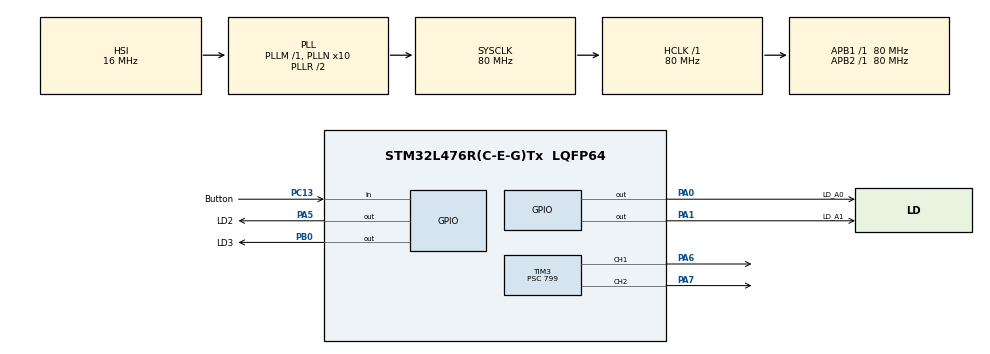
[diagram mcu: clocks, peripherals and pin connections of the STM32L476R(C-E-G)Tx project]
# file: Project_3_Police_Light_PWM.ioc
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Mcu.Family=STM32L4
Mcu.Name=STM32L476R(C-E-G)Tx
Mcu.Package=LQFP64
NVIC.PriorityGroup=NVIC_PRIORITYGROUP_4
NVIC.TIM3_IRQn=true\:10\:0\:true\:false\:true\:true\:true\:true
NVIC.TIM4_IRQn=true\:10\:0\:true\:false\:true\:true\:true\:true
PA0.GPIO_Label=LD_A0
PA0.Signal=GPIO_Output
PA1.GPIO_Label=LD_A1
PA1.Signal=GPIO_Output
PA5.GPIO_Label=LD2
PA5.Signal=GPIO_Output
PA6.Signal=S_TIM3_CH1
PA7.Signal=S_TIM3_CH2
PB0.GPIO_Label=LD3
PB0.Signal=GPIO_Output
PC13.GPIO_Label=Button
PC13.Signal=GPIO_Input
ProjectManager.HeapSize=0x200
ProjectManager.StackSize=0x400
ProjectManager.TargetToolchain=STM32CubeIDE
RCC.ADCFreq_Value=64000000
RCC.AHBFreq_Value=80000000
RCC.APB1Freq_Value=80000000
RCC.APB1TimFreq_Value=80000000
RCC.APB2Freq_Value=80000000
RCC.APB2TimFreq_Value=80000000
RCC.CortexFreq_Value=80000000
RCC.HCLKFreq_Value=80000000
RCC.HSE_VALUE=8000000
RCC.HSI_VALUE=16000000
RCC.LSE_VALUE=32768
RCC.MSI_VALUE=4000000
RCC.PLLN=10
RCC.PLLSourceVirtual=RCC_PLLSOURCE_HSI
RCC.PREFETCH_ENABLE=1
RCC.SYSCLKFreq_VALUE=80000000
RCC.SYSCLKSource=RCC_SYSCLKSOURCE_PLLCLK
RCC.USBFreq_Value=64000000
RCC.VCOOutputFreq_Value=160000000
SH.S_TIM3_CH1.0=TIM3_CH1,PWM Generation1 CH1
SH.S_TIM3_CH2.0=TIM3_CH2,PWM Generation2 CH2
TIM3.Channel-Output\ Compare3\ No\ Output=TIM_CHANNEL_3
TIM3.Channel-PWM\ Generation1\ CH1=TIM_CHANNEL_1
TIM3.Channel-PWM\ Generation2\ CH2=TIM_CHANNEL_2
TIM3.OCPolarity_1=TIM_OCPOLARITY_LOW
TIM3.OCPolarity_2=TIM_OCPOLARITY_HIGH
TIM3.OCPolarity_3=TIM_OCPOLARITY_HIGH
TIM3.Period=9999
TIM3.Prescaler=799
TIM3.Pulse-Output\ Compare3\ No\ Output=5000
TIM3.Pulse-PWM\ Generation1\ CH1=5000
TIM3.Pulse-PWM\ Generation2\ CH2=5000
TIM4.Channel-Output\ Compare1\ No\ Output=TIM_CHANNEL_1
TIM4.Period=9999
TIM4.Prescaler=799
TIM4.Pulse-Output\ Compare1\ No\ Output=5000
VP_TIM3_VS_ClockSourceINT.Mode=Internal
VP_TIM3_VS_no_output3.Mode=Output Compare3 No Output
VP_TIM4_VS_no_output1.Mode=Output Compare1 No Output
board=NUCLEO-L476RG

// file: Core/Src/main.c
/* USER CODE BEGIN Header */
/**
  ******************************************************************************
  * @file           : main.c
  * @brief          : Main program body
  ******************************************************************************
  * @attention
  *
  * Copyright (c) 2024 STMicroelectronics.
  * All rights reserved.
  *
  * This software is licensed under terms that can be found in the LICENSE file
  * in the root directory of this software component.
  * If no LICENSE file comes with this software, it is provided AS-IS.
  *
  ******************************************************************************
  */
/* USER CODE END Header */
#include "main.h"

TIM_HandleTypeDef htim3;
TIM_HandleTypeDef htim4;

void SystemClock_Config(void);
static void MX_GPIO_Init(void);
static void MX_TIM3_Init(void);
static void MX_TIM4_Init(void);

/* USER CODE BEGIN 0 */

void HAL_TIM_PeriodElapsedCallback(TIM_HandleTypeDef *htim)
{
  if (htim == &htim3) {
    HAL_GPIO_TogglePin(LD2_GPIO_Port, LD2_Pin);
  }
}
/* USER CODE END 0 */

int main(void)
{

  /* MCU Configuration--------------------------------------------------------*/

  /* Reset of all peripherals, Initializes the Flash interface and the Systick. */
  HAL_Init();

  /* Configure the system clock */
  SystemClock_Config();

  /* Initialize all configured peripherals */
  MX_GPIO_Init();
  MX_TIM3_Init();
  MX_TIM4_Init();
  /* USER CODE BEGIN 2 */

  HAL_TIM_Base_Start_IT(&htim3);
  HAL_TIM_PWM_Start(&htim3, TIM_CHANNEL_1);
  HAL_TIM_PWM_Start(&htim3, TIM_CHANNEL_2);

  /* USER CODE END 2 */

  /* Infinite loop */
  while (1)
  {

  }
}

void SystemClock_Config(void)
{
  RCC_OscInitTypeDef RCC_OscInitStruct = {0};
  RCC_ClkInitTypeDef RCC_ClkInitStruct = {0};

  /** Configure the main internal regulator output voltage
  */
  if (HAL_PWREx_ControlVoltageScaling(PWR_REGULATOR_VOLTAGE_SCALE1) != HAL_OK)
  {
    Error_Handler();
  }

  /** Initializes the RCC Oscillators according to the specified parameters
  * in the RCC_OscInitTypeDef structure.
  */
  RCC_OscInitStruct.OscillatorType = RCC_OSCILLATORTYPE_HSI;
  RCC_OscInitStruct.HSIState = RCC_HSI_ON;
  RCC_OscInitStruct.HSICalibrationValue = RCC_HSICALIBRATION_DEFAULT;
  RCC_OscInitStruct.PLL.PLLState = RCC_PLL_ON;
  RCC_OscInitStruct.PLL.PLLSource = RCC_PLLSOURCE_HSI;
  RCC_OscInitStruct.PLL.PLLM = 1;
  RCC_OscInitStruct.PLL.PLLN = 10;
  RCC_OscInitStruct.PLL.PLLP = RCC_PLLP_DIV7;
  RCC_OscInitStruct.PLL.PLLQ = RCC_PLLQ_DIV2;
  RCC_OscInitStruct.PLL.PLLR = RCC_PLLR_DIV2;
  if (HAL_RCC_OscConfig(&RCC_OscInitStruct) != HAL_OK)
  {
    Error_Handler();
  }

  /** Initializes the CPU, AHB and APB buses clocks
  */
  RCC_ClkInitStruct.ClockType = RCC_CLOCKTYPE_HCLK|RCC_CLOCKTYPE_SYSCLK
                              |RCC_CLOCKTYPE_PCLK1|RCC_CLOCKTYPE_PCLK2;
  RCC_ClkInitStruct.SYSCLKSource = RCC_SYSCLKSOURCE_PLLCLK;
  RCC_ClkInitStruct.AHBCLKDivider = RCC_SYSCLK_DIV1;
  RCC_ClkInitStruct.APB1CLKDivider = RCC_HCLK_DIV1;
  RCC_ClkInitStruct.APB2CLKDivider = RCC_HCLK_DIV1;

  if (HAL_RCC_ClockConfig(&RCC_ClkInitStruct, FLASH_LATENCY_4) != HAL_OK)
  {
    Error_Handler();
  }
}

static void MX_TIM3_Init(void)
{

  TIM_ClockConfigTypeDef sClockSourceConfig = {0};
  TIM_MasterConfigTypeDef sMasterConfig = {0};
  TIM_OC_InitTypeDef sConfigOC = {0};

  htim3.Instance = TIM3;
  htim3.Init.Prescaler = 799;
  htim3.Init.CounterMode = TIM_COUNTERMODE_UP;
  htim3.Init.Period = 9999;
  htim3.Init.ClockDivision = TIM_CLOCKDIVISION_DIV1;
  htim3.Init.AutoReloadPreload = TIM_AUTORELOAD_PRELOAD_DISABLE;
  if (HAL_TIM_Base_Init(&htim3) != HAL_OK)
  {
    Error_Handler();
  }
  sClockSourceConfig.ClockSource = TIM_CLOCKSOURCE_INTERNAL;
  if (HAL_TIM_ConfigClockSource(&htim3, &sClockSourceConfig) != HAL_OK)
  {
    Error_Handler();
  }
  if (HAL_TIM_PWM_Init(&htim3) != HAL_OK)
  {
    Error_Handler();
  }
  if (HAL_TIM_OC_Init(&htim3) != HAL_OK)
  {
    Error_Handler();
  }
  sMasterConfig.MasterOutputTrigger = TIM_TRGO_RESET;
  sMasterConfig.MasterSlaveMode = TIM_MASTERSLAVEMODE_DISABLE;
  if (HAL_TIMEx_MasterConfigSynchronization(&htim3, &sMasterConfig) != HAL_OK)
  {
    Error_Handler();
  }
  sConfigOC.OCMode = TIM_OCMODE_PWM1;
  sConfigOC.Pulse = 5000;
  sConfigOC.OCPolarity = TIM_OCPOLARITY_LOW;
  sConfigOC.OCFastMode = TIM_OCFAST_DISABLE;
  if (HAL_TIM_PWM_ConfigChannel(&htim3, &sConfigOC, TIM_CHANNEL_1) != HAL_OK)
  {
    Error_Handler();
  }
  sConfigOC.OCPolarity = TIM_OCPOLARITY_HIGH;
  if (HAL_TIM_PWM_ConfigChannel(&htim3, &sConfigOC, TIM_CHANNEL_2) != HAL_OK)
  {
    Error_Handler();
  }
  sConfigOC.OCMode = TIM_OCMODE_TIMING;
  if (HAL_TIM_OC_ConfigChannel(&htim3, &sConfigOC, TIM_CHANNEL_3) != HAL_OK)
  {
    Error_Handler();
  }
  HAL_TIM_MspPostInit(&htim3);

}

static void MX_TIM4_Init(void)
{

  TIM_MasterConfigTypeDef sMasterConfig = {0};
  TIM_OC_InitTypeDef sConfigOC = {0};

  htim4.Instance = TIM4;
  htim4.Init.Prescaler = 799;
  htim4.Init.CounterMode = TIM_COUNTERMODE_UP;
  htim4.Init.Period = 9999;
  htim4.Init.ClockDivision = TIM_CLOCKDIVISION_DIV1;
  htim4.Init.AutoReloadPreload = TIM_AUTORELOAD_PRELOAD_DISABLE;
  if (HAL_TIM_OC_Init(&htim4) != HAL_OK)
  {
    Error_Handler();
  }
  sMasterConfig.MasterOutputTrigger = TIM_TRGO_RESET;
  sMasterConfig.MasterSlaveMode = TIM_MASTERSLAVEMODE_DISABLE;
  if (HAL_TIMEx_MasterConfigSynchronization(&htim4, &sMasterConfig) != HAL_OK)
  {
    Error_Handler();
  }
  sConfigOC.OCMode = TIM_OCMODE_TIMING;
  sConfigOC.Pulse = 5000;
  sConfigOC.OCPolarity = TIM_OCPOLARITY_HIGH;
  sConfigOC.OCFastMode = TIM_OCFAST_DISABLE;
  if (HAL_TIM_OC_ConfigChannel(&htim4, &sConfigOC, TIM_CHANNEL_1) != HAL_OK)
  {
    Error_Handler();
  }

}

static void MX_GPIO_Init(void)
{
  GPIO_InitTypeDef GPIO_InitStruct = {0};

  /* GPIO Ports Clock Enable */
  __HAL_RCC_GPIOC_CLK_ENABLE();
  __HAL_RCC_GPIOA_CLK_ENABLE();
  __HAL_RCC_GPIOB_CLK_ENABLE();

  /*Configure GPIO pin Output Level */
  HAL_GPIO_WritePin(GPIOA, LD_A0_Pin|LD_A1_Pin|LD2_Pin, GPIO_PIN_RESET);

  /*Configure GPIO pin Output Level */
  HAL_GPIO_WritePin(LD3_GPIO_Port, LD3_Pin, GPIO_PIN_RESET);

  /*Configure GPIO pin : Button_Pin */
  GPIO_InitStruct.Pin = Button_Pin;
  GPIO_InitStruct.Mode = GPIO_MODE_INPUT;
  GPIO_InitStruct.Pull = GPIO_NOPULL;
  HAL_GPIO_Init(Button_GPIO_Port, &GPIO_InitStruct);

  /*Configure GPIO pins : LD_A0_Pin LD_A1_Pin LD2_Pin */
  GPIO_InitStruct.Pin = LD_A0_Pin|LD_A1_Pin|LD2_Pin;
  GPIO_InitStruct.Mode = GPIO_MODE_OUTPUT_PP;
  GPIO_InitStruct.Pull = GPIO_NOPULL;
  GPIO_InitStruct.Speed = GPIO_SPEED_FREQ_LOW;
  HAL_GPIO_Init(GPIOA, &GPIO_InitStruct);

  /*Configure GPIO pin : LD3_Pin */
  GPIO_InitStruct.Pin = LD3_Pin;
  GPIO_InitStruct.Mode = GPIO_MODE_OUTPUT_PP;
  GPIO_InitStruct.Pull = GPIO_NOPULL;
  GPIO_InitStruct.Speed = GPIO_SPEED_FREQ_LOW;
  HAL_GPIO_Init(LD3_GPIO_Port, &GPIO_InitStruct);

}

void Error_Handler(void)
{
  __disable_irq();
  while (1)
  {
  }
}
